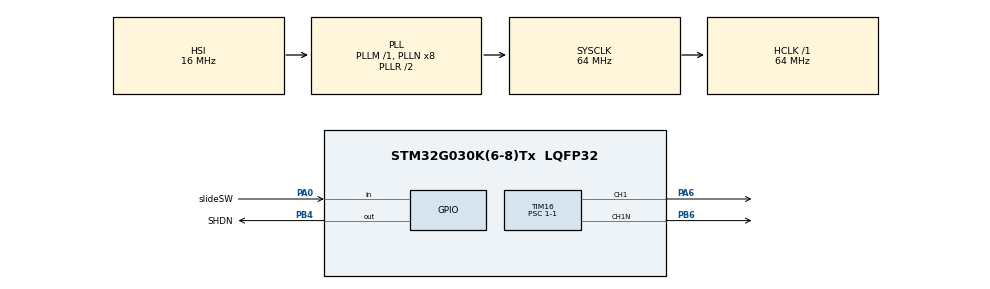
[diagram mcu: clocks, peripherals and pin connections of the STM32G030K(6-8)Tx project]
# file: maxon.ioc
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Mcu.Family=STM32G0
Mcu.Name=STM32G030K(6-8)Tx
Mcu.Package=LQFP32
PA0.GPIO_Label=slideSW
PA0.Signal=GPIO_Input
PA6.Signal=S_TIM16_CH1
PB4.GPIO_Label=SHDN
PB4.Signal=GPIO_Output
PB6.Mode=PWM Generation1 CH1 CH1N
PB6.Signal=TIM16_CH1N
ProjectManager.HeapSize=0x200
ProjectManager.StackSize=0x400
ProjectManager.TargetToolchain=STM32CubeIDE
RCC.ADCFreq_Value=64000000
RCC.AHBFreq_Value=64000000
RCC.CortexFreq_Value=64000000
RCC.EXTERNAL_CLOCK_VALUE=12288000
RCC.HCLKFreq_Value=64000000
RCC.HSE_VALUE=8000000
RCC.HSI_VALUE=16000000
RCC.LSE_VALUE=32768
RCC.SYSCLKFreq_VALUE=64000000
RCC.SYSCLKSource=RCC_SYSCLKSOURCE_PLLCLK
RCC.VCOOutputFreq_Value=128000000
SH.S_TIM16_CH1.0=TIM16_CH1,PWM Generation1 CH1 CH1N
TIM16.Channel=TIM_CHANNEL_1
TIM16.OCFastMode_PWM=TIM_OCFAST_ENABLE
TIM16.Period=640-1
TIM16.Prescaler=1-1
VP_TIM16_VS_ClockSourceINT.Mode=Enable_Timer
board=custom

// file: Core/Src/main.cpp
/* USER CODE BEGIN Header */
/**
  ******************************************************************************
  * @file           : main.c
  * @brief          : Main program body
  ******************************************************************************
  * @attention
  *
  * Copyright (c) 2024 STMicroelectronics.
  * All rights reserved.
  *
  * This software is licensed under terms that can be found in the LICENSE file
  * in the root directory of this software component.
  * If no LICENSE file comes with this software, it is provided AS-IS.
  *
  ******************************************************************************
  */
/* USER CODE END Header */
#include "main.h"

/* USER CODE BEGIN Includes */
#include "maxon.h"

/* USER CODE END Includes */

TIM_HandleTypeDef htim16;

/* USER CODE BEGIN PV */
uint16_t value = 0;

/* USER CODE END PV */

void SystemClock_Config(void);
static void MX_GPIO_Init(void);
static void MX_TIM16_Init(void);

int main(void)
{

  /* MCU Configuration--------------------------------------------------------*/

  /* Reset of all peripherals, Initializes the Flash interface and the Systick. */
  HAL_Init();

  /* Configure the system clock */
  SystemClock_Config();

  /* Initialize all configured peripherals */
  MX_GPIO_Init();
  MX_TIM16_Init();
  /* USER CODE BEGIN 2 */
  MAXON maxon(&htim16, TIM_CHANNEL_1, SHDN_GPIO_Port, SHDN_Pin);

  /* USER CODE END 2 */

  /* Infinite loop */
  while (1)
  {

    /* USER CODE BEGIN 3 */
	  if(HAL_GPIO_ReadPin (slideSW_GPIO_Port, slideSW_Pin) == 0){
		  if(value < 290){
			  value++;
			  HAL_Delay(1);
		  }
	  }else{
		  if(value > 0){
			  value--;
			  HAL_Delay(1);
		  }
	  }
	  maxon.move(value);

  }
  /* USER CODE END 3 */
}

void SystemClock_Config(void)
{
  RCC_OscInitTypeDef RCC_OscInitStruct = {0};
  RCC_ClkInitTypeDef RCC_ClkInitStruct = {0};

  /** Configure the main internal regulator output voltage
  */
  HAL_PWREx_ControlVoltageScaling(PWR_REGULATOR_VOLTAGE_SCALE1);

  /** Initializes the RCC Oscillators according to the specified parameters
  * in the RCC_OscInitTypeDef structure.
  */
  RCC_OscInitStruct.OscillatorType = RCC_OSCILLATORTYPE_HSI;
  RCC_OscInitStruct.HSIState = RCC_HSI_ON;
  RCC_OscInitStruct.HSIDiv = RCC_HSI_DIV1;
  RCC_OscInitStruct.HSICalibrationValue = RCC_HSICALIBRATION_DEFAULT;
  RCC_OscInitStruct.PLL.PLLState = RCC_PLL_ON;
  RCC_OscInitStruct.PLL.PLLSource = RCC_PLLSOURCE_HSI;
  RCC_OscInitStruct.PLL.PLLM = RCC_PLLM_DIV1;
  RCC_OscInitStruct.PLL.PLLN = 8;
  RCC_OscInitStruct.PLL.PLLP = RCC_PLLP_DIV2;
  RCC_OscInitStruct.PLL.PLLR = RCC_PLLR_DIV2;
  if (HAL_RCC_OscConfig(&RCC_OscInitStruct) != HAL_OK)
  {
    Error_Handler();
  }

  /** Initializes the CPU, AHB and APB buses clocks
  */
  RCC_ClkInitStruct.ClockType = RCC_CLOCKTYPE_HCLK|RCC_CLOCKTYPE_SYSCLK
                              |RCC_CLOCKTYPE_PCLK1;
  RCC_ClkInitStruct.SYSCLKSource = RCC_SYSCLKSOURCE_PLLCLK;
  RCC_ClkInitStruct.AHBCLKDivider = RCC_SYSCLK_DIV1;
  RCC_ClkInitStruct.APB1CLKDivider = RCC_HCLK_DIV1;

  if (HAL_RCC_ClockConfig(&RCC_ClkInitStruct, FLASH_LATENCY_2) != HAL_OK)
  {
    Error_Handler();
  }
}

static void MX_TIM16_Init(void)
{

  TIM_OC_InitTypeDef sConfigOC = {0};
  TIM_BreakDeadTimeConfigTypeDef sBreakDeadTimeConfig = {0};

  htim16.Instance = TIM16;
  htim16.Init.Prescaler = 1-1;
  htim16.Init.CounterMode = TIM_COUNTERMODE_UP;
  htim16.Init.Period = 640-1;
  htim16.Init.ClockDivision = TIM_CLOCKDIVISION_DIV1;
  htim16.Init.RepetitionCounter = 0;
  htim16.Init.AutoReloadPreload = TIM_AUTORELOAD_PRELOAD_DISABLE;
  if (HAL_TIM_Base_Init(&htim16) != HAL_OK)
  {
    Error_Handler();
  }
  if (HAL_TIM_PWM_Init(&htim16) != HAL_OK)
  {
    Error_Handler();
  }
  sConfigOC.OCMode = TIM_OCMODE_PWM1;
  sConfigOC.Pulse = 0;
  sConfigOC.OCPolarity = TIM_OCPOLARITY_HIGH;
  sConfigOC.OCNPolarity = TIM_OCNPOLARITY_HIGH;
  sConfigOC.OCFastMode = TIM_OCFAST_ENABLE;
  sConfigOC.OCIdleState = TIM_OCIDLESTATE_RESET;
  sConfigOC.OCNIdleState = TIM_OCNIDLESTATE_RESET;
  if (HAL_TIM_PWM_ConfigChannel(&htim16, &sConfigOC, TIM_CHANNEL_1) != HAL_OK)
  {
    Error_Handler();
  }
  sBreakDeadTimeConfig.OffStateRunMode = TIM_OSSR_DISABLE;
  sBreakDeadTimeConfig.OffStateIDLEMode = TIM_OSSI_DISABLE;
  sBreakDeadTimeConfig.LockLevel = TIM_LOCKLEVEL_OFF;
  sBreakDeadTimeConfig.DeadTime = 0;
  sBreakDeadTimeConfig.BreakState = TIM_BREAK_DISABLE;
  sBreakDeadTimeConfig.BreakPolarity = TIM_BREAKPOLARITY_HIGH;
  sBreakDeadTimeConfig.BreakFilter = 0;
  sBreakDeadTimeConfig.AutomaticOutput = TIM_AUTOMATICOUTPUT_DISABLE;
  if (HAL_TIMEx_ConfigBreakDeadTime(&htim16, &sBreakDeadTimeConfig) != HAL_OK)
  {
    Error_Handler();
  }
  HAL_TIM_MspPostInit(&htim16);

}

static void MX_GPIO_Init(void)
{
  GPIO_InitTypeDef GPIO_InitStruct = {0};

  /* GPIO Ports Clock Enable */
  __HAL_RCC_GPIOA_CLK_ENABLE();
  __HAL_RCC_GPIOB_CLK_ENABLE();

  /*Configure GPIO pin Output Level */
  HAL_GPIO_WritePin(SHDN_GPIO_Port, SHDN_Pin, GPIO_PIN_RESET);

  /*Configure GPIO pin : slideSW_Pin */
  GPIO_InitStruct.Pin = slideSW_Pin;
  GPIO_InitStruct.Mode = GPIO_MODE_INPUT;
  GPIO_InitStruct.Pull = GPIO_NOPULL;
  HAL_GPIO_Init(slideSW_GPIO_Port, &GPIO_InitStruct);

  /*Configure GPIO pin : SHDN_Pin */
  GPIO_InitStruct.Pin = SHDN_Pin;
  GPIO_InitStruct.Mode = GPIO_MODE_OUTPUT_PP;
  GPIO_InitStruct.Pull = GPIO_NOPULL;
  GPIO_InitStruct.Speed = GPIO_SPEED_FREQ_LOW;
  HAL_GPIO_Init(SHDN_GPIO_Port, &GPIO_InitStruct);

}

void Error_Handler(void)
{
  __disable_irq();
  while (1)
  {
  }
}
